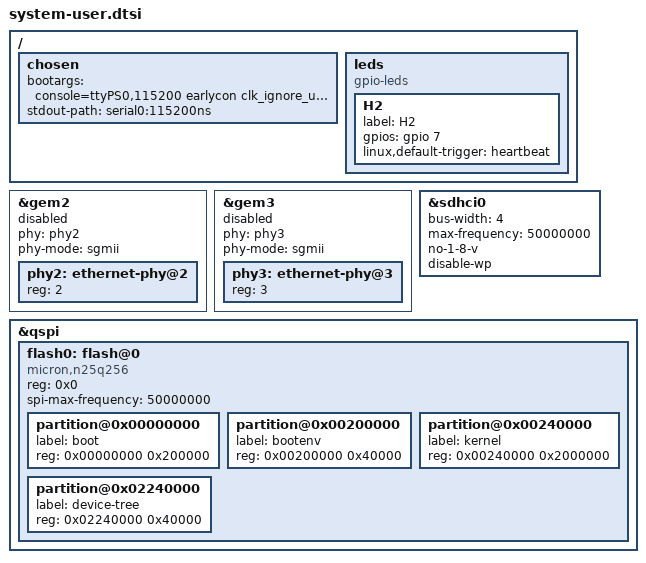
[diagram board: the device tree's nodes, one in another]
/include/ "system-conf.dtsi"
/ {

    chosen {
/*          bootargs = "console=ttyPS1,115200 earlyprintk root=/dev/mmcblk0p2 rootfstype=ext4 nolock rw rootwait ip=192.168.0.177::192.168.0.1:255.255.255.0:fmc133v:eth0:off";*/
            bootargs = "console=ttyPS0,115200 earlycon clk_ignore_unused earlyprintk root=/dev/mmcblk0p2 rw rootwait ip=dhcp";
            stdout-path = "serial0:115200ns";
        };

    leds {
        compatible = "gpio-leds";

        H2 {
            label = "H2";
            gpios = <&gpio 7 0>;
            linux,default-trigger = "heartbeat";
        };
    };
};

&gem2 {
    status = "disabled";
    phy = <&phy2>;
    phy-mode = "sgmii";
    phy2: ethernet-phy@2 {
        reg = <2>;
    };
};

&gem3 {
    status = "disabled";
    phy = <&phy3>;
    phy-mode = "sgmii";
    phy3: ethernet-phy@3 {
        reg = <3>;
    };
};

&sdhci0 {
        status = "okay";
        bus-width = <4>;
        max-frequency = <50000000>;
        no-1-8-v;
        disable-wp;
};

&qspi {
    #address-cells = <1>;
    #size-cells = <0>;
    flash0: flash@0 {
        compatible = "micron,n25q256";
        reg = <0x0>;
        #address-cells = <1>;
        #size-cells = <1>;
        spi-max-frequency = <50000000>;
        partition@0x00000000 {
            label = "boot";
            reg = <0x00000000 0x200000>;
        };
        partition@0x00200000 {
            label = "bootenv";
            reg = <0x00200000 0x40000>;
        };
        partition@0x00240000 {
            label = "kernel";
            reg = <0x00240000 0x2000000>;
        };
        partition@0x02240000 {
            label = "device-tree";
            reg = <0x02240000 0x40000>;
        };
    };
};
